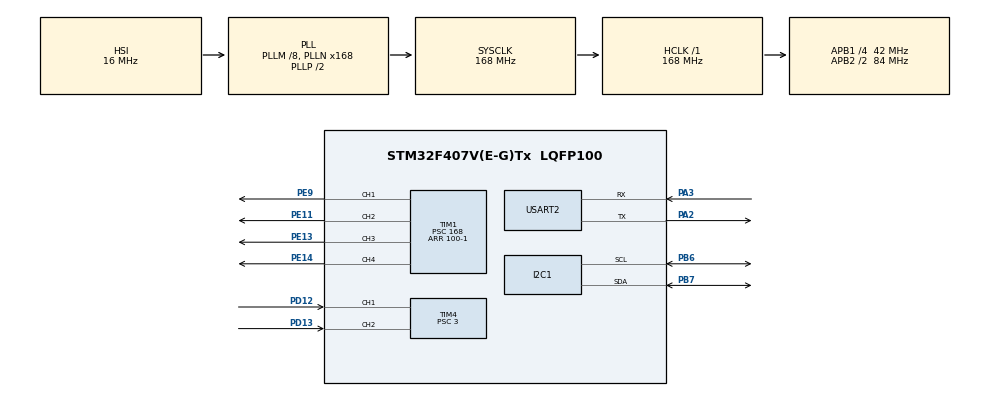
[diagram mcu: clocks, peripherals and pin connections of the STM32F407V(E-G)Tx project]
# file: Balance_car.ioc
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Mcu.Family=STM32F4
Mcu.Name=STM32F407V(E-G)Tx
Mcu.Package=LQFP100
NVIC.PriorityGroup=NVIC_PRIORITYGROUP_4
NVIC.TIM2_IRQn=true\:1\:0\:true\:false\:true\:true\:true
NVIC.TIM4_IRQn=true\:0\:0\:false\:false\:true\:true\:true
PA13.Mode=Serial_Wire
PA13.Signal=SYS_JTMS-SWDIO
PA14.Mode=Serial_Wire
PA14.Signal=SYS_JTCK-SWCLK
PA2.Mode=Asynchronous
PA2.Signal=USART2_TX
PA3.Mode=Asynchronous
PA3.Signal=USART2_RX
PB6.Mode=I2C
PB6.Signal=I2C1_SCL
PB7.Mode=I2C
PB7.Signal=I2C1_SDA
PD12.Signal=S_TIM4_CH1
PD13.Signal=S_TIM4_CH2
PE11.Signal=S_TIM1_CH2
PE13.Signal=S_TIM1_CH3
PE14.Signal=S_TIM1_CH4
PE9.Signal=S_TIM1_CH1
PH0-OSC_IN.Mode=HSE-External-Oscillator
PH0-OSC_IN.Signal=RCC_OSC_IN
PH1-OSC_OUT.Mode=HSE-External-Oscillator
PH1-OSC_OUT.Signal=RCC_OSC_OUT
ProjectManager.HeapSize=0x200
ProjectManager.StackSize=0x400
ProjectManager.TargetToolchain=MDK-ARM V5.27
RCC.48MHZClocksFreq_Value=84000000
RCC.AHBFreq_Value=168000000
RCC.APB1CLKDivider=RCC_HCLK_DIV4
RCC.APB1Freq_Value=42000000
RCC.APB1TimFreq_Value=84000000
RCC.APB2CLKDivider=RCC_HCLK_DIV2
RCC.APB2Freq_Value=84000000
RCC.APB2TimFreq_Value=168000000
RCC.CortexFreq_Value=168000000
RCC.HCLKFreq_Value=168000000
RCC.HSE_VALUE=8000000
RCC.HSI_VALUE=16000000
RCC.LSE_VALUE=32768
RCC.PLLM=8
RCC.PLLN=168
RCC.SYSCLKFreq_VALUE=168000000
RCC.SYSCLKSource=RCC_SYSCLKSOURCE_PLLCLK
RCC.VCOOutputFreq_Value=336000000
SH.S_TIM1_CH1.0=TIM1_CH1,PWM Generation1 CH1
SH.S_TIM1_CH2.0=TIM1_CH2,PWM Generation2 CH2
SH.S_TIM1_CH3.0=TIM1_CH3,PWM Generation3 CH3
SH.S_TIM1_CH4.0=TIM1_CH4,PWM Generation4 CH4
SH.S_TIM4_CH1.0=TIM4_CH1,Encoder_Interface
SH.S_TIM4_CH2.0=TIM4_CH2,Encoder_Interface
TIM1.Channel-PWM\ Generation1\ CH1=TIM_CHANNEL_1
TIM1.Channel-PWM\ Generation2\ CH2=TIM_CHANNEL_2
TIM1.Channel-PWM\ Generation3\ CH3=TIM_CHANNEL_3
TIM1.Channel-PWM\ Generation4\ CH4=TIM_CHANNEL_4
TIM1.Period=100-1
TIM1.Prescaler=168
TIM2.AutoReloadPreload=TIM_AUTORELOAD_PRELOAD_ENABLE
TIM2.Period=9999
TIM2.Prescaler=168
TIM4.EncoderMode=TIM_ENCODERMODE_TI12
TIM4.Prescaler=3
USART2.VirtualMode=VM_ASYNC
VP_TIM2_VS_ClockSourceINT.Mode=Internal
board=custom

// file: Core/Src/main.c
/* USER CODE BEGIN Header */
/**
  ******************************************************************************
  * @file           : main.c
  * @brief          : Main program body
  ******************************************************************************
  * @attention
  *
  * <h2><center>&copy; Copyright (c) 2021 STMicroelectronics.
  * All rights reserved.</center></h2>
  *
  * This software component is licensed by ST under BSD 3-Clause license,
  * the "License"; You may not use this file except in compliance with the
  * License. You may obtain a copy of the License at:
  *                        opensource.org/licenses/BSD-3-Clause
  *
  ******************************************************************************
  */
/* USER CODE END Header */
#include "main.h"
#include "i2c.h"
#include "tim.h"
#include "usart.h"
#include "gpio.h"

/* USER CODE BEGIN Includes */
#include "bsp_imu.h"
#include "stdio.h"
/* USER CODE END Includes */

void SystemClock_Config(void);

int main(void)
{

  /* MCU Configuration--------------------------------------------------------*/

  /* Reset of all peripherals, Initializes the Flash interface and the Systick. */
  HAL_Init();

  /* Configure the system clock */
  SystemClock_Config();

  /* Initialize all configured peripherals */
  MX_GPIO_Init();
  MX_TIM1_Init();
  MX_TIM2_Init();
  MX_TIM4_Init();
  MX_I2C1_Init();
  MX_USART2_UART_Init();
  /* USER CODE BEGIN 2 */
	MPU6050Init();
  /* USER CODE END 2 */

  /* Infinite loop */
  while (1)
  {

    /* USER CODE BEGIN 3 */
    mpu_get_data();
    imu_ahrs_update();
    imu_attitude_update();
	  printf("imu = %f,rol = %f,pit = %f\r\n",imu.rol,imu.yaw,imu.pit);
		HAL_Delay(500);
	}
  /* USER CODE END 3 */
}

void SystemClock_Config(void)
{
  RCC_OscInitTypeDef RCC_OscInitStruct = {0};
  RCC_ClkInitTypeDef RCC_ClkInitStruct = {0};

  /** Configure the main internal regulator output voltage
  */
  __HAL_RCC_PWR_CLK_ENABLE();
  __HAL_PWR_VOLTAGESCALING_CONFIG(PWR_REGULATOR_VOLTAGE_SCALE1);
  /** Initializes the RCC Oscillators according to the specified parameters
  * in the RCC_OscInitTypeDef structure.
  */
  RCC_OscInitStruct.OscillatorType = RCC_OSCILLATORTYPE_HSI;
  RCC_OscInitStruct.HSIState = RCC_HSI_ON;
  RCC_OscInitStruct.HSICalibrationValue = RCC_HSICALIBRATION_DEFAULT;
  RCC_OscInitStruct.PLL.PLLState = RCC_PLL_ON;
  RCC_OscInitStruct.PLL.PLLSource = RCC_PLLSOURCE_HSI;
  RCC_OscInitStruct.PLL.PLLM = 8;
  RCC_OscInitStruct.PLL.PLLN = 168;
  RCC_OscInitStruct.PLL.PLLP = RCC_PLLP_DIV2;
  RCC_OscInitStruct.PLL.PLLQ = 4;
  if (HAL_RCC_OscConfig(&RCC_OscInitStruct) != HAL_OK)
  {
    Error_Handler();
  }
  /** Initializes the CPU, AHB and APB buses clocks
  */
  RCC_ClkInitStruct.ClockType = RCC_CLOCKTYPE_HCLK|RCC_CLOCKTYPE_SYSCLK
                              |RCC_CLOCKTYPE_PCLK1|RCC_CLOCKTYPE_PCLK2;
  RCC_ClkInitStruct.SYSCLKSource = RCC_SYSCLKSOURCE_PLLCLK;
  RCC_ClkInitStruct.AHBCLKDivider = RCC_SYSCLK_DIV1;
  RCC_ClkInitStruct.APB1CLKDivider = RCC_HCLK_DIV4;
  RCC_ClkInitStruct.APB2CLKDivider = RCC_HCLK_DIV2;

  if (HAL_RCC_ClockConfig(&RCC_ClkInitStruct, FLASH_LATENCY_5) != HAL_OK)
  {
    Error_Handler();
  }
}

/* USER CODE BEGIN 4 */
int fputc(int ch, FILE *f)
{
  HAL_UART_Transmit(&huart2, (uint8_t *)&ch, sizeof(ch), 500);
  return ch;
}
// int fgetc(FILE *f)
// {
//   uint8_t ch = 0;
//   HAL_UART_Receive(&huart2, &ch, 1, 0xffff);
//   return ch;
// }
/* USER CODE END 4 */

void Error_Handler(void)
{
  __disable_irq();
  while (1)
  {
  }
}

/************************ (C) COPYRIGHT STMicroelectronics *****END OF FILE****/
